# apollo510 register map
Vendor: Ambiq Micro; Series: Apollo; File version: 1.0
CPU: CM55 r1p1, little endian, MPU, FPU, double-precision FPU, DSP, I-cache, D-cache, VTOR, ITCM, DTCM, 4 interrupt priority bits, 0 interrupts, 8 SAU regions
Registers are 32-bit, read-write, reset 0x0 unless marked. A register's access mark holds for its fields unless they carry their own. Offsets are from the block's base; [hi:lo] are bit positions; 'fields as' and 'values as' point back to an identical list.

## IOSLAVEFD0 — SPI Full Duplex Slaves
Base 0x40035000
Same registers: IOSLAVEFD1 0x40036000
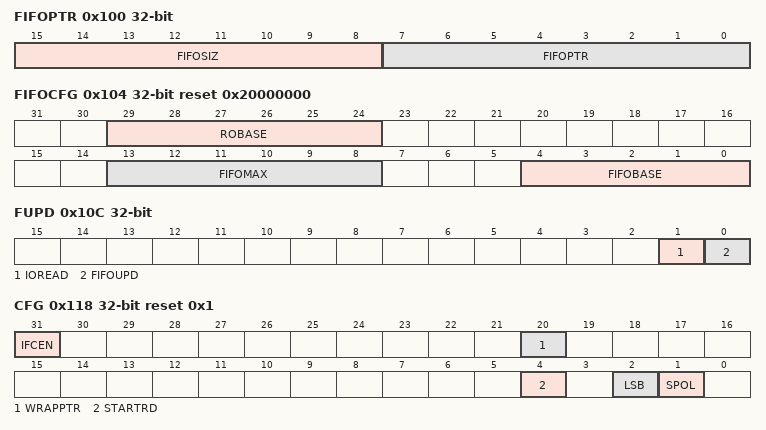
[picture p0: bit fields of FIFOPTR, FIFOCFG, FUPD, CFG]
0x100 FIFOPTR — Current FIFO Pointer
  [15:8] FIFOSIZ — The number of bytes currently in the hardware FIFO.
  [7:0] FIFOPTR — Current FIFO pointer.
0x104 FIFOCFG reset 0x20000000 — FIFO Configuration
  [29:24] ROBASE — Defines the read-only area. The IO Slave read-only area is situated in LRAM at (ROBASE*8) to (FIFOBASE*8-1)
  [13:8] FIFOMAX — These bits hold the maximum FIFO address in 8 byte segments. It is also the beginning of the RAM area of the LRAM. Note that no RAM area is configured if FIFOMAX is set to 0x1F.
  [4:0] FIFOBASE — These bits hold the base address of the I/O FIFO in 8 byte segments. The IO Slave FIFO is situated in LRAM at (FIFOBASE*8) to (FIFOMAX*8-1).
0x108 FIFOTHR — FIFO Threshold Configuration
  [7:0] FIFOTHR — FIFO size interrupt threshold.
0x10C FUPD — FIFO Update Status
  [1] IOREAD — This bitfield indicates an IO read is active.
  [0] FIFOUPD — This bit indicates that a FIFO update is underway.
0x110 FIFOCTR — Overall FIFO Counter
  [9:0] FIFOCTR — Virtual FIFO byte count
0x114 FIFOINC — Overall FIFO Counter Increment
  [9:0] FIFOINC — Increment the Overall FIFO Counter by this value on a write
0x118 CFG reset 0x1 — I/O Slave Configuration
  [31] IFCEN — IOSLAVE interface enable.
    0=DIS (Disable the IOSLAVE); 1=EN (Enable the IOSLAVE)
  [20] WRAPPTR — Address pointer wrap mode enable.
    0=NOWRAP (Address pointer does not wrap around to FIFOBASE*8 after it reaches FIFOMAX*8-1. Additionally, the address pointer does not automatically skip Direct Area locations 0x78 to 0x7F, so care must be taken that the host does not inadvertently write to the Host Registers during a data transfer.); 1=WRAP (Address pointer wraps around to FIFOBASE*8 after it reaches FIFOMAX*8-1 to accommodate any length transfers. In addition, the address pointer automatically skips Direct Area locations 0x78 to 0x7F (if the FIFO Area encompasses these locations) to avoid writing to the Host Registers.)
  [4] STARTRD — This bit holds the cycle to initiate an I/O RAM read.
    0=LATE (Initiate I/O RAM read late in each transferred byte.); 1=EARLY (Initiate I/O RAM read early in each transferred byte.)
  [2] LSB — This bit selects the transfer bit ordering.
    0=MSB_FIRST (Data is assumed to be sent and received with MSB first.); 1=LSB_FIRST (Data is assumed to be sent and received with LSB first.)
  [1] SPOL — This bit selects SPI polarity.
    0=SPI_MODES_0_3 (Polarity 0, handles SPI modes 0 and 3.); 1=SPI_MODES_1_2 (Polarity 1, handles SPI modes 1 and 2.)
0x11C PRENC — I/O Slave Interrupt Priority Encode
  [4:0] PRENC — These bits hold the priority encode of the REGACC interrupts.
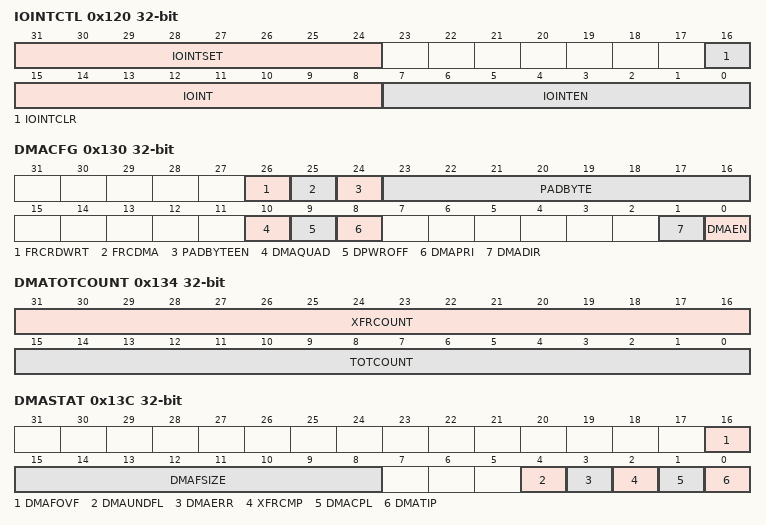
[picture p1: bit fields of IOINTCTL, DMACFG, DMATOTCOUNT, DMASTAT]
0x120 IOINTCTL — I/O Interrupt Control
  [31:24] IOINTSET — These bits set the IOINT interrupts when written with a 1.
  [16] IOINTCLR — This bit clears all of the IOINT interrupts when written with a 1.
  [15:8] IOINT — These bits read the IOINT interrupts.
  [7:0] IOINTEN — These read-only bits indicate whether the IOINT interrupts are enabled.
0x124 GENADD — General Address Data
  [7:0] GADATA — The data supplied on the last General Address reference.
0x128 ADDPTR — Address pointer
  [7:0] ADDPTR — The current value in the Address pointer.
0x130 DMACFG — Configuration control of the DMA process, including the direction of DMA, and enablement of DMA
  [26] FRCRDWRT — Select DMA transfer force direction
    0=FRCWRT (Force DMA transfer write); 1=FRCRD (Force DMA transfer read)
  [25] FRCDMA — Force DMA transfer read/write independent of R/W bit in interface command
    0=NOFORCE (Do not force read/write); 1=FORCE (Force DMA read or DMA write, depending on FRCRDWRT bit)
  [24] PADBYTEEN — PAD byte enable.
    0=DIS (Disable PAD Byte Function); 1=EN (Enable PAD Byte Function)
  [23:16] PADBYTE — PAD byte value.
  [10] DMAQUAD — Sets the Priority of the DMA request
    0=SINGLE (Transfer one word per DMA request); 1=QUAD (Transfer up to four words per DMA request)
  [9] DPWROFF — Power off module after DMA is complete. If this bit is active, the module will request to power off the supply it is attached to. If there are other units still requiring power from the same domain, power down will not be performed.
    0=DIS (Power off disabled); 1=EN (Power off enabled)
  [8] DMAPRI — Sets the Priority of the DMA request
    0=LOW (Low Priority (service as best effort)); 1=HIGH (High Priority (service immediately))
  [1] DMADIR — Direction
    0=P2M (Peripheral to Memory (SRAM) transaction. To be set when doing DMA read operations, ie reading data from external devices.); 1=M2P (Memory to Peripheral transaction. To be set when doing DMA write operations, ie writing data to external devices.)
  [0] DMAEN — DMA Enable. Setting this bit to EN will start the DMA operation. This should be the last DMA related register set prior to issuing the command
    0=DIS (Disable DMA Function); 1=EN (Enable DMA Function)
0x134 DMATOTCOUNT — Contains the number of bytes to be transferred for this DMA transaction. This register is decremented as the data is transferred.
  [31:16] XFRCOUNT — This bitfield holds the number of bytes transferred on the interface.
  [15:0] TOTCOUNT — This bitfield holds the number of bytes transferred to/from memory during a DMA transfer.
0x138 DMATARGADDR — The source or destination address internal the SRAM for the DMA data. For write operations, this can only be SRAM data (ADDR bit 28 = 1); For read operations, this can be either SRAM or FLASH (ADDR bit 28 = 0)
  [31:0] TARGADDR — Bits [28:0] of the target byte address for source of DMA (either read or write). The address can be any byte alignment, and does not have to be word aligned. In cases of non-word aligned addresses, the DMA logic will take care of ensuring only the target bytes are read/written.
0x13C DMASTAT — Status of the DMA operation currently in progress.
  [16] DMAFOVF — DMA FIFO size overflow
  [15:8] DMAFSIZE — DMA FIFO size not transferred
  [4] DMAUNDFL — DMA Error. This active high bit signals an underflow was encountered during a DMA write operation. The bit can be cleared by writing to 0. Once set, this bit will remain set until cleared by software.
  [3] DMAERR — DMA Error. This active high bit signals an error was encountered during the DMA operation. The bit can be cleared by writing to 0. Once set, this bit will remain set until cleared by software.
  [2] XFRCMP — DMA Error. This active high bit signals when the transfer is complete from teh Host. The bit can be cleared by writing to 0. Once set, this bit will remain set until cleared by software.
  [1] DMACPL — DMA Transfer Complete. This signals the end of the DMA operation. This bit can be cleared by writing to 0, and will also be cleared when a new DMA is started.
  [0] DMATIP — DMA Transfer In Progress indicator. 1 will indicate that a DMA transfer is active. The DMA transfer may be waiting on data, transferring data, or waiting for priority. All of these will be indicated with a 1. A 0 will indicate that the DMA is fully complete and no further transactions will be done. This bit is read only.
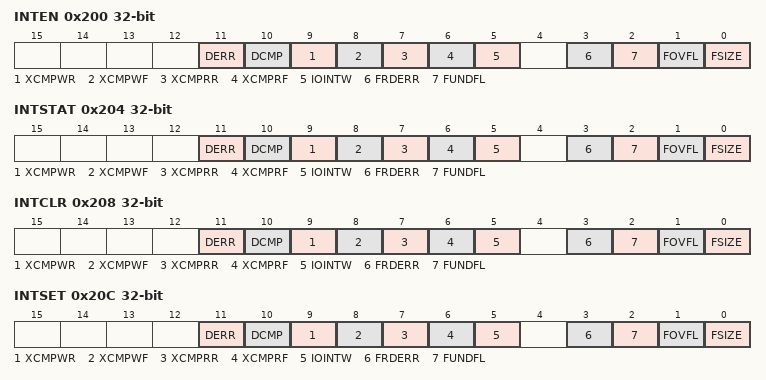
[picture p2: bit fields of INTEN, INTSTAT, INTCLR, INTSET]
0x200 INTEN — Set bits in this register to allow this module to generate the corresponding interrupt.
  [11] DERR — DMA Error encountered during the processing of the DMA command. The DMA error could occur when the memory access specified in the DMA operation is not available or incorrectly specified.
  [10] DCMP — DMA Complete. Processing of the DMA operation has completed and the DMA submodule is returned into the idle state
  [9] XCMPWR — Transfer complete interrupt, write to register space.
  [8] XCMPWF — Transfer complete interrupt, write to FIFO space.
  [7] XCMPRR — Transfer complete interrupt, read from register space.
  [6] XCMPRF — Transfer complete interrupt, read from FIFO space.
  [5] IOINTW — IO Write interrupt.
  [3] FRDERR — FIFO Read Error interrupt.
  [2] FUNDFL — FIFO Underflow interrupt.
  [1] FOVFL — FIFO Overflow interrupt.
  [0] FSIZE — FIFO Size interrupt.
0x204 INTSTAT — Read bits from this register to discover the cause of a recent interrupt.
  fields as INTEN
0x208 INTCLR — Write a 1 to a bit in this register to clear the interrupt status associated with that bit.
  fields as INTEN
0x20C INTSET — Write a 1 to a bit in this register to instantly generate an interrupt from this module. (Generally used for testing purposes).
  fields as INTEN
0x210 REGACCINTEN — Set bits in this register to allow this module to generate the corresponding interrupt.
  [31:0] REGACC — Register access interrupts.
0x214 REGACCINTSTAT — Read bits from this register to discover the cause of a recent interrupt.
  [31:0] REGACC — Register access interrupts.
0x218 REGACCINTCLR — Write a 1 to a bit in this register to clear the interrupt status associated with that bit.
  [31:0] REGACC — Register access interrupts.
0x21C REGACCINTSET — Write a 1 to a bit in this register to instantly generate an interrupt from this module. (Generally used for testing purposes).
  [31:0] REGACC — Register access interrupts.

## IOSLAVE — I2C/SPI Slave
Base 0x40034000
Registers as IOSLAVEFD0; these are added or differ:
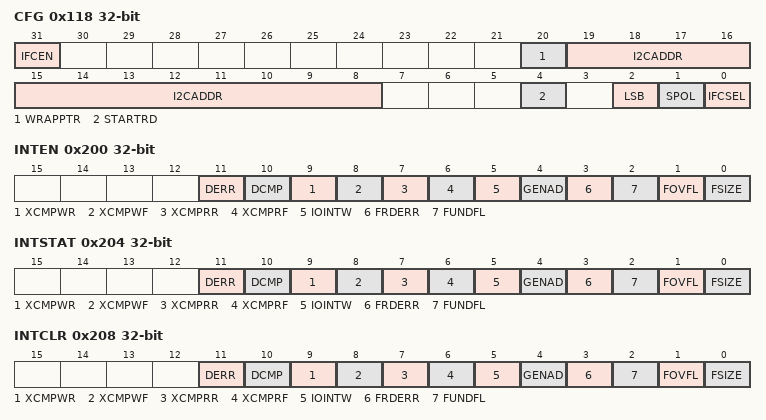
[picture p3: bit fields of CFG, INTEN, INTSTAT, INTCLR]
0x118 CFG — I/O Slave Configuration
  [31] IFCEN — IOSLAVE interface enable.
    0=DIS (Disable the IOSLAVE); 1=EN (Enable the IOSLAVE)
  [20] WRAPPTR — Address pointer wrap mode enable.
    values as IOSLAVEFD0.CFG.WRAPPTR
  [19:8] I2CADDR — 7-bit or 10-bit I2C device address.
  [4] STARTRD — This bit holds the cycle to initiate an I/O RAM read.
    0=LATE (Initiate I/O RAM read late in each transferred byte.); 1=EARLY (Initiate I/O RAM read early in each transferred byte.)
  [2] LSB — This bit selects the transfer bit ordering.
    0=MSB_FIRST (Data is assumed to be sent and received with MSB first.); 1=LSB_FIRST (Data is assumed to be sent and received with LSB first.)
  [1] SPOL — This bit selects SPI polarity.
    0=SPI_MODES_0_3 (Polarity 0, handles SPI modes 0 and 3.); 1=SPI_MODES_1_2 (Polarity 1, handles SPI modes 1 and 2.)
  [0] IFCSEL — This bit selects the I/O interface.
    0=I2C (Selects I2C interface for the IO Slave.); 1=SPI (Selects SPI interface for the IO Slave.)
0x200 INTEN — Set bits in this register to allow this module to generate the corresponding interrupt.
  [11] DERR — DMA Error encountered during the processing of the DMA command. The DMA error could occur when the memory access specified in the DMA operation is not available or incorrectly specified.
  [10] DCMP — DMA Complete. Processing of the DMA operation has completed and the DMA submodule is returned into the idle state
  [9] XCMPWR — Transfer complete interrupt, write to register space.
  [8] XCMPWF — Transfer complete interrupt, write to FIFO space.
  [7] XCMPRR — Transfer complete interrupt, read from register space.
  [6] XCMPRF — Transfer complete interrupt, read from FIFO space.
  [5] IOINTW — IO Write interrupt.
  [4] GENAD — I2C General Address interrupt.
  [3] FRDERR — FIFO Read Error interrupt.
  [2] FUNDFL — FIFO Underflow interrupt.
  [1] FOVFL — FIFO Overflow interrupt.
  [0] FSIZE — FIFO Size interrupt.
0x204 INTSTAT — Read bits from this register to discover the cause of a recent interrupt.
  fields as INTEN
0x208 INTCLR — Write a 1 to a bit in this register to clear the interrupt status associated with that bit.
  fields as INTEN
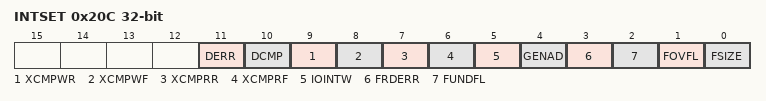
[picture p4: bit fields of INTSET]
0x20C INTSET — Write a 1 to a bit in this register to instantly generate an interrupt from this module. (Generally used for testing purposes).
  fields as INTEN
